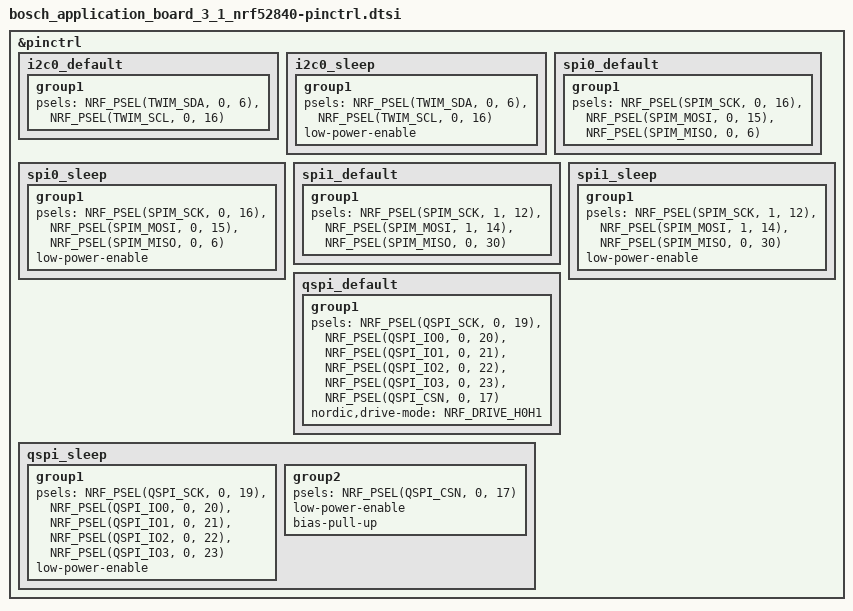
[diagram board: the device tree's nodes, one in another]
/*
 * Copyright (c) 2022 Nordic Semiconductor
 * SPDX-License-Identifier: Apache-2.0
 */

&pinctrl {

	i2c0_default: i2c0_default {
		group1 {
			psels = <NRF_PSEL(TWIM_SDA, 0, 6)>,
				<NRF_PSEL(TWIM_SCL, 0, 16)>;
		};
	};

	i2c0_sleep: i2c0_sleep {
		group1 {
			psels = <NRF_PSEL(TWIM_SDA, 0, 6)>,
				<NRF_PSEL(TWIM_SCL, 0, 16)>;
			low-power-enable;
		};
	};

	spi0_default: spi0_default {
		group1 {
			psels = <NRF_PSEL(SPIM_SCK, 0, 16)>,
				<NRF_PSEL(SPIM_MOSI, 0, 15)>,
				<NRF_PSEL(SPIM_MISO, 0, 6)>;
		};
	};

	spi0_sleep: spi0_sleep {
		group1 {
			psels = <NRF_PSEL(SPIM_SCK, 0, 16)>,
				<NRF_PSEL(SPIM_MOSI, 0, 15)>,
				<NRF_PSEL(SPIM_MISO, 0, 6)>;
			low-power-enable;
		};
	};

	spi1_default: spi1_default {
		group1 {
			psels = <NRF_PSEL(SPIM_SCK, 1, 12)>,
				<NRF_PSEL(SPIM_MOSI, 1, 14)>,
				<NRF_PSEL(SPIM_MISO, 0, 30)>;
		};
	};

	spi1_sleep: spi1_sleep {
		group1 {
			psels = <NRF_PSEL(SPIM_SCK, 1, 12)>,
				<NRF_PSEL(SPIM_MOSI, 1, 14)>,
				<NRF_PSEL(SPIM_MISO, 0, 30)>;
			low-power-enable;
		};
	};

	qspi_default: qspi_default {
		group1 {
			psels = <NRF_PSEL(QSPI_SCK, 0, 19)>,
					<NRF_PSEL(QSPI_IO0, 0, 20)>,
					<NRF_PSEL(QSPI_IO1, 0, 21)>,
					<NRF_PSEL(QSPI_IO2, 0, 22)>,
					<NRF_PSEL(QSPI_IO3, 0, 23)>,
					<NRF_PSEL(QSPI_CSN, 0, 17)>;
			nordic,drive-mode = <NRF_DRIVE_H0H1>;
		};
	};

	qspi_sleep: qspi_sleep {
		group1 {
			psels = <NRF_PSEL(QSPI_SCK, 0, 19)>,
					<NRF_PSEL(QSPI_IO0, 0, 20)>,
					<NRF_PSEL(QSPI_IO1, 0, 21)>,
					<NRF_PSEL(QSPI_IO2, 0, 22)>,
					<NRF_PSEL(QSPI_IO3, 0, 23)>;
			low-power-enable;
		};
		group2 {
			psels = <NRF_PSEL(QSPI_CSN, 0, 17)>;
			low-power-enable;
			bias-pull-up;
		};
	};

};
